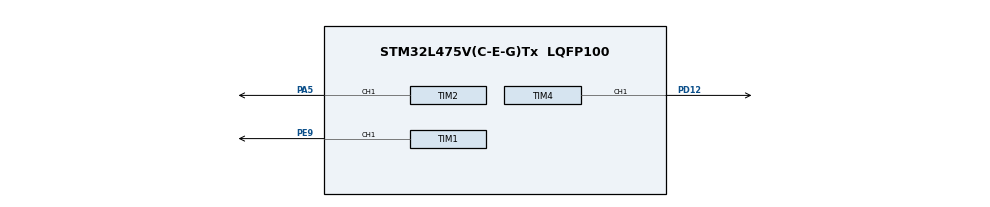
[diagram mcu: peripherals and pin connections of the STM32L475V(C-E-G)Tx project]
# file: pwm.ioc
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Mcu.Family=STM32L4
Mcu.Name=STM32L475V(C-E-G)Tx
Mcu.Package=LQFP100
NVIC.PriorityGroup=NVIC_PRIORITYGROUP_4
NVIC.TIM1_UP_TIM16_IRQn=true\:15\:0\:false\:false\:true\:false\:true
NVIC.TimeBase=TIM1_UP_TIM16_IRQn
NVIC.TimeBaseIP=TIM16
PA5.Signal=S_TIM2_CH1
PD12.Signal=S_TIM4_CH1
PE9.Signal=S_TIM1_CH1
ProjectManager.HeapSize=0x200
ProjectManager.StackSize=0x400
ProjectManager.TargetToolchain=EWARM V8.32
RCC.HSE_VALUE=8000000
RCC.HSI_VALUE=16000000
RCC.LSE_VALUE=32768
RCC.MSI_VALUE=4000000
RCC.VCOOutputFreq_Value=32000000
SH.S_TIM1_CH1.0=TIM1_CH1,PWM Generation1 CH1
SH.S_TIM2_CH1.0=TIM2_CH1,PWM Generation1 CH1
SH.S_TIM4_CH1.0=TIM4_CH1,PWM Generation1 CH1
TIM1.Channel-PWM\ Generation1\ CH1=TIM_CHANNEL_1
TIM1.Period=2000-1
TIM1.Prescaler=1080-1
TIM2.Channel-PWM\ Generation1\ CH1=TIM_CHANNEL_1
TIM2.Period=62499
TIM2.Prescaler=127
TIM2.Pulse-PWM\ Generation1\ CH1=31250
TIM4.Channel-PWM\ Generation1\ CH1=TIM_CHANNEL_1
TIM4.Period=2000-1
TIM4.Prescaler=1080-1
VP_SYS_VS_tim16.Mode=TIM16
VP_TIM1_VS_ClockSourceINT.Mode=Internal
VP_TIM2_VS_ClockSourceINT.Mode=Internal
VP_TIM4_VS_ClockSourceINT.Mode=Internal
board=custom

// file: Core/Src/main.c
/* USER CODE BEGIN Header */
/**
  ******************************************************************************
  * @file           : main.c
  * @brief          : Main program body
  ******************************************************************************
  * @attention
  *
  * <h2><center>&copy; Copyright (c) 2021 STMicroelectronics.
  * All rights reserved.</center></h2>
  *
  * This software component is licensed by ST under BSD 3-Clause license,
  * the "License"; You may not use this file except in compliance with the
  * License. You may obtain a copy of the License at:
  *                        opensource.org/licenses/BSD-3-Clause
  *
  ******************************************************************************
  */
/* USER CODE END Header */
#include "main.h"

TIM_HandleTypeDef htim1;
TIM_HandleTypeDef htim2;
TIM_HandleTypeDef htim4;

void SystemClock_Config(void);
static void MX_GPIO_Init(void);
static void MX_TIM1_Init(void);
static void MX_TIM2_Init(void);
static void MX_TIM4_Init(void);

/* USER CODE BEGIN 0 */
void user_pwm_setvalue(uint16_t value)
{
    TIM_OC_InitTypeDef sConfigOC;

    sConfigOC.OCMode = TIM_OCMODE_PWM1;
    sConfigOC.Pulse = value;
    sConfigOC.OCPolarity = TIM_OCPOLARITY_HIGH;
    sConfigOC.OCFastMode = TIM_OCFAST_DISABLE;
    HAL_TIM_PWM_ConfigChannel(&htim2, &sConfigOC, TIM_CHANNEL_1);
    HAL_TIM_PWM_Start(&htim2, TIM_CHANNEL_1);
}
/* USER CODE END 0 */

int main(void)
{

  /* MCU Configuration--------------------------------------------------------*/

  /* Reset of all peripherals, Initializes the Flash interface and the Systick. */
  HAL_Init();

  /* Configure the system clock */
  SystemClock_Config();

  /* Initialize all configured peripherals */
  MX_GPIO_Init();
  MX_TIM1_Init();
  MX_TIM2_Init();
  MX_TIM4_Init();
  /* USER CODE BEGIN 2 */
  int16_t pwm_value = 0;
  int16_t step = 0;
  HAL_TIM_PWM_Start(&htim2, TIM_CHANNEL_1);
  /* USER CODE END 2 */

  /* Infinite loop */
  while (1)
  {
	  //HAL_GPIO_TogglePin(GPIOB, GPIO_PIN_14);
    HAL_GPIO_TogglePin(GPIOA, GPIO_PIN_5);
    HAL_Delay(1000);
    if(pwm_value == 0) step = 100;
    if(pwm_value == 2000) step = -100;
    pwm_value += step;
    user_pwm_setvalue(pwm_value);
  }
}

void SystemClock_Config(void)
{
  RCC_OscInitTypeDef RCC_OscInitStruct = {0};
  RCC_ClkInitTypeDef RCC_ClkInitStruct = {0};

  /** Configure the main internal regulator output voltage
  */
  if (HAL_PWREx_ControlVoltageScaling(PWR_REGULATOR_VOLTAGE_SCALE1) != HAL_OK)
  {
    Error_Handler();
  }
  /** Initializes the RCC Oscillators according to the specified parameters
  * in the RCC_OscInitTypeDef structure.
  */
  RCC_OscInitStruct.OscillatorType = RCC_OSCILLATORTYPE_MSI;
  RCC_OscInitStruct.MSIState = RCC_MSI_ON;
  RCC_OscInitStruct.MSICalibrationValue = 0;
  RCC_OscInitStruct.MSIClockRange = RCC_MSIRANGE_6;
  RCC_OscInitStruct.PLL.PLLState = RCC_PLL_NONE;
  if (HAL_RCC_OscConfig(&RCC_OscInitStruct) != HAL_OK)
  {
    Error_Handler();
  }
  /** Initializes the CPU, AHB and APB buses clocks
  */
  RCC_ClkInitStruct.ClockType = RCC_CLOCKTYPE_HCLK|RCC_CLOCKTYPE_SYSCLK
                              |RCC_CLOCKTYPE_PCLK1|RCC_CLOCKTYPE_PCLK2;
  RCC_ClkInitStruct.SYSCLKSource = RCC_SYSCLKSOURCE_MSI;
  RCC_ClkInitStruct.AHBCLKDivider = RCC_SYSCLK_DIV1;
  RCC_ClkInitStruct.APB1CLKDivider = RCC_HCLK_DIV1;
  RCC_ClkInitStruct.APB2CLKDivider = RCC_HCLK_DIV1;

  if (HAL_RCC_ClockConfig(&RCC_ClkInitStruct, FLASH_LATENCY_0) != HAL_OK)
  {
    Error_Handler();
  }
}

static void MX_TIM1_Init(void)
{

  TIM_ClockConfigTypeDef sClockSourceConfig = {0};
  TIM_MasterConfigTypeDef sMasterConfig = {0};
  TIM_OC_InitTypeDef sConfigOC = {0};
  TIM_BreakDeadTimeConfigTypeDef sBreakDeadTimeConfig = {0};

  htim1.Instance = TIM1;
  htim1.Init.Prescaler = 1080-1;
  htim1.Init.CounterMode = TIM_COUNTERMODE_UP;
  htim1.Init.Period = 2000-1;
  htim1.Init.ClockDivision = TIM_CLOCKDIVISION_DIV1;
  htim1.Init.RepetitionCounter = 0;
  htim1.Init.AutoReloadPreload = TIM_AUTORELOAD_PRELOAD_DISABLE;
  if (HAL_TIM_Base_Init(&htim1) != HAL_OK)
  {
    Error_Handler();
  }
  sClockSourceConfig.ClockSource = TIM_CLOCKSOURCE_INTERNAL;
  if (HAL_TIM_ConfigClockSource(&htim1, &sClockSourceConfig) != HAL_OK)
  {
    Error_Handler();
  }
  if (HAL_TIM_PWM_Init(&htim1) != HAL_OK)
  {
    Error_Handler();
  }
  sMasterConfig.MasterOutputTrigger = TIM_TRGO_RESET;
  sMasterConfig.MasterOutputTrigger2 = TIM_TRGO2_RESET;
  sMasterConfig.MasterSlaveMode = TIM_MASTERSLAVEMODE_DISABLE;
  if (HAL_TIMEx_MasterConfigSynchronization(&htim1, &sMasterConfig) != HAL_OK)
  {
    Error_Handler();
  }
  sConfigOC.OCMode = TIM_OCMODE_PWM1;
  sConfigOC.Pulse = 0;
  sConfigOC.OCPolarity = TIM_OCPOLARITY_HIGH;
  sConfigOC.OCNPolarity = TIM_OCNPOLARITY_HIGH;
  sConfigOC.OCFastMode = TIM_OCFAST_DISABLE;
  sConfigOC.OCIdleState = TIM_OCIDLESTATE_RESET;
  sConfigOC.OCNIdleState = TIM_OCNIDLESTATE_RESET;
  if (HAL_TIM_PWM_ConfigChannel(&htim1, &sConfigOC, TIM_CHANNEL_1) != HAL_OK)
  {
    Error_Handler();
  }
  sBreakDeadTimeConfig.OffStateRunMode = TIM_OSSR_DISABLE;
  sBreakDeadTimeConfig.OffStateIDLEMode = TIM_OSSI_DISABLE;
  sBreakDeadTimeConfig.LockLevel = TIM_LOCKLEVEL_OFF;
  sBreakDeadTimeConfig.DeadTime = 0;
  sBreakDeadTimeConfig.BreakState = TIM_BREAK_DISABLE;
  sBreakDeadTimeConfig.BreakPolarity = TIM_BREAKPOLARITY_HIGH;
  sBreakDeadTimeConfig.BreakFilter = 0;
  sBreakDeadTimeConfig.Break2State = TIM_BREAK2_DISABLE;
  sBreakDeadTimeConfig.Break2Polarity = TIM_BREAK2POLARITY_HIGH;
  sBreakDeadTimeConfig.Break2Filter = 0;
  sBreakDeadTimeConfig.AutomaticOutput = TIM_AUTOMATICOUTPUT_DISABLE;
  if (HAL_TIMEx_ConfigBreakDeadTime(&htim1, &sBreakDeadTimeConfig) != HAL_OK)
  {
    Error_Handler();
  }
  HAL_TIM_MspPostInit(&htim1);

}

static void MX_TIM2_Init(void)
{

  TIM_ClockConfigTypeDef sClockSourceConfig = {0};
  TIM_MasterConfigTypeDef sMasterConfig = {0};
  TIM_OC_InitTypeDef sConfigOC = {0};

  htim2.Instance = TIM2;
  htim2.Init.Prescaler = 127;
  htim2.Init.CounterMode = TIM_COUNTERMODE_UP;
  htim2.Init.Period = 62499;
  htim2.Init.ClockDivision = TIM_CLOCKDIVISION_DIV1;
  htim2.Init.AutoReloadPreload = TIM_AUTORELOAD_PRELOAD_DISABLE;
  if (HAL_TIM_Base_Init(&htim2) != HAL_OK)
  {
    Error_Handler();
  }
  sClockSourceConfig.ClockSource = TIM_CLOCKSOURCE_INTERNAL;
  if (HAL_TIM_ConfigClockSource(&htim2, &sClockSourceConfig) != HAL_OK)
  {
    Error_Handler();
  }
  if (HAL_TIM_PWM_Init(&htim2) != HAL_OK)
  {
    Error_Handler();
  }
  sMasterConfig.MasterOutputTrigger = TIM_TRGO_RESET;
  sMasterConfig.MasterSlaveMode = TIM_MASTERSLAVEMODE_DISABLE;
  if (HAL_TIMEx_MasterConfigSynchronization(&htim2, &sMasterConfig) != HAL_OK)
  {
    Error_Handler();
  }
  sConfigOC.OCMode = TIM_OCMODE_PWM1;
  sConfigOC.Pulse = 31250;
  sConfigOC.OCPolarity = TIM_OCPOLARITY_HIGH;
  sConfigOC.OCFastMode = TIM_OCFAST_DISABLE;
  if (HAL_TIM_PWM_ConfigChannel(&htim2, &sConfigOC, TIM_CHANNEL_1) != HAL_OK)
  {
    Error_Handler();
  }
  HAL_TIM_MspPostInit(&htim2);

}

static void MX_TIM4_Init(void)
{

  TIM_ClockConfigTypeDef sClockSourceConfig = {0};
  TIM_MasterConfigTypeDef sMasterConfig = {0};
  TIM_OC_InitTypeDef sConfigOC = {0};

  htim4.Instance = TIM4;
  htim4.Init.Prescaler = 1080-1;
  htim4.Init.CounterMode = TIM_COUNTERMODE_UP;
  htim4.Init.Period = 2000-1;
  htim4.Init.ClockDivision = TIM_CLOCKDIVISION_DIV1;
  htim4.Init.AutoReloadPreload = TIM_AUTORELOAD_PRELOAD_DISABLE;
  if (HAL_TIM_Base_Init(&htim4) != HAL_OK)
  {
    Error_Handler();
  }
  sClockSourceConfig.ClockSource = TIM_CLOCKSOURCE_INTERNAL;
  if (HAL_TIM_ConfigClockSource(&htim4, &sClockSourceConfig) != HAL_OK)
  {
    Error_Handler();
  }
  if (HAL_TIM_PWM_Init(&htim4) != HAL_OK)
  {
    Error_Handler();
  }
  sMasterConfig.MasterOutputTrigger = TIM_TRGO_RESET;
  sMasterConfig.MasterSlaveMode = TIM_MASTERSLAVEMODE_DISABLE;
  if (HAL_TIMEx_MasterConfigSynchronization(&htim4, &sMasterConfig) != HAL_OK)
  {
    Error_Handler();
  }
  sConfigOC.OCMode = TIM_OCMODE_PWM1;
  sConfigOC.Pulse = 0;
  sConfigOC.OCPolarity = TIM_OCPOLARITY_HIGH;
  sConfigOC.OCFastMode = TIM_OCFAST_DISABLE;
  if (HAL_TIM_PWM_ConfigChannel(&htim4, &sConfigOC, TIM_CHANNEL_1) != HAL_OK)
  {
    Error_Handler();
  }
  HAL_TIM_MspPostInit(&htim4);

}

static void MX_GPIO_Init(void)
{

  /* GPIO Ports Clock Enable */
  __HAL_RCC_GPIOA_CLK_ENABLE();
  __HAL_RCC_GPIOE_CLK_ENABLE();
  __HAL_RCC_GPIOD_CLK_ENABLE();

}

void HAL_TIM_PeriodElapsedCallback(TIM_HandleTypeDef *htim)
{
  if (htim->Instance == TIM16) {
    HAL_IncTick();
  }
}

void Error_Handler(void)
{
  __disable_irq();
  while (1)
  {
  }
}

/************************ (C) COPYRIGHT STMicroelectronics *****END OF FILE****/
